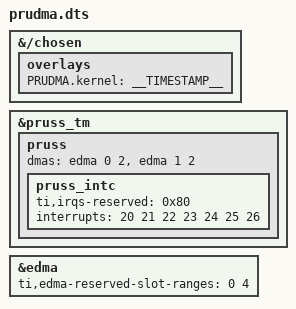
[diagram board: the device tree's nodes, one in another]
/dts-v1/;
/plugin/;

#include <dt-bindings/pinctrl/am33xx-l4.h>
#include <dt-bindings/pinctrl/am33xx.h>

&{/chosen} {
        overlays {
                PRUDMA.kernel = __TIMESTAMP__;
        };
};

/* in am33xx-l4.dtsi */
&pruss_tm {
	pruss {
                /* 0 and 1 are fixed for PRU-initiated DMAs, see TRM ... */
		dmas = <&edma 0 2>, <&edma 1 2>;
		dma-names = "prucpy0", "prucpy1";

	        pruss_intc {
			/* This is host_intr7 i.e., 8th bit to say that this
			* outgoing irq is not meant for the ARM core. */
			ti,irqs-reserved = /bits/ 8 <0x80>; /* BIT(7) */

                        interrupt-names = "host_intr0", "host_intr1",
                                         "host_intr2", "host_intr3",
                                         "host_intr4", "host_intr5",
                                         "host_intr6";
			interrupts = <20 21 22 23 24 25 26>;
	        }
	}
}

/* in am33xx.dtsi */
&edma {
	ti,edma-reserved-slot-ranges = <0 4>;
}






